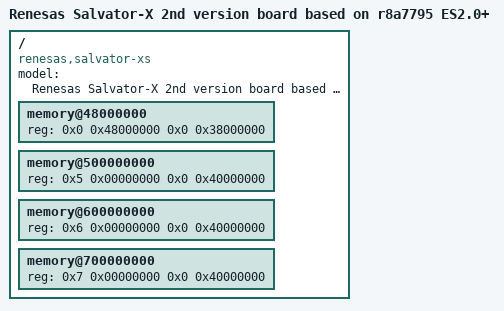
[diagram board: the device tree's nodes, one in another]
/*
 * Device Tree Source for the Salvator-X 2nd version board with R-Car H3 ES2.0
 *
 * Copyright (C) 2015-2017 Renesas Electronics Corp.
 *
 * This file is licensed under the terms of the GNU General Public License
 * version 2.  This program is licensed "as is" without any warranty of any
 * kind, whether express or implied.
 */

/dts-v1/;
#include "r8a7795.dtsi"
#include "salvator-xs.dtsi"

/ {
	model = "Renesas Salvator-X 2nd version board based on r8a7795 ES2.0+";
	compatible = "renesas,salvator-xs", "renesas,r8a7795";

	memory@48000000 {
		device_type = "memory";
		/* first 128MB is reserved for secure area. */
		reg = <0x0 0x48000000 0x0 0x38000000>;
	};

	memory@500000000 {
		device_type = "memory";
		reg = <0x5 0x00000000 0x0 0x40000000>;
	};

	memory@600000000 {
		device_type = "memory";
		reg = <0x6 0x00000000 0x0 0x40000000>;
	};

	memory@700000000 {
		device_type = "memory";
		reg = <0x7 0x00000000 0x0 0x40000000>;
	};
};

